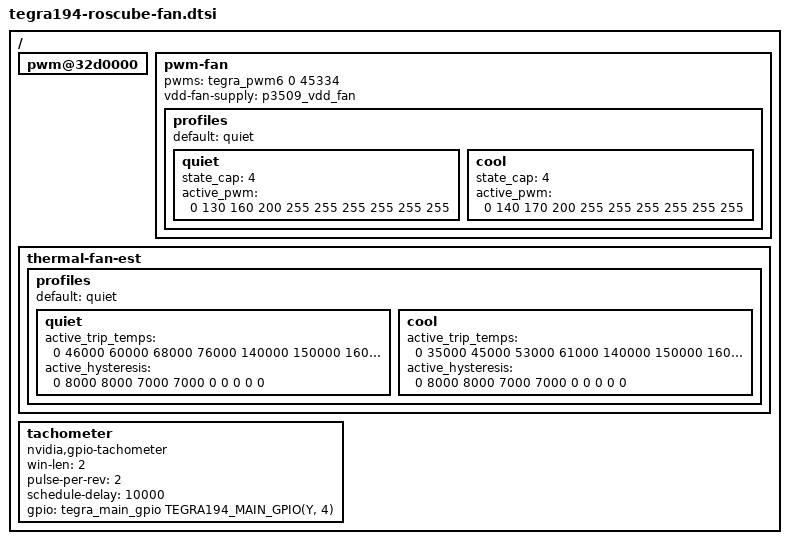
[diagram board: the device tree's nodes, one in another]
/*
 * Copyright (c) 2020, ADLINK Technology Inc. Advanced Robotic Platform Group.  All rights reserved.
 *
 * This program is free software; you can redistribute it and/or modify
 * it under the terms of the GNU General Public License as published by
 * the Free Software Foundation; version 2 of the License.
 *
 * This program is distributed in the hope that it will be useful, but WITHOUT
 * ANY WARRANTY; without even the implied warranty of MERCHANTABILITY or
 * FITNESS FOR A PARTICULAR PURPOSE.  See the GNU General Public License for
 * more details.
 */

 / {

	pwm@32d0000 {
		status = "okay";
	};

	pwm-fan {
		pwms = <&tegra_pwm6 0 45334>;
		vdd-fan-supply = <&p3509_vdd_fan>;
		profiles {
			default = "quiet";
			quiet {
				state_cap = <4>;
				active_pwm = <0 130 160 200 255 255 255 255 255 255>;
			};
			cool {
				state_cap = <4>;
				active_pwm = <0 140 170 200 255 255 255 255 255 255>;
			};
		};
	};
	
	thermal-fan-est {
		profiles {
			default = "quiet";
			quiet {
				active_trip_temps = <0 46000 60000 68000 76000
						140000 150000 160000 170000 180000>;
				active_hysteresis = <0 8000 8000 7000 7000
						0 0 0 0 0>;
			};
			cool {
				active_trip_temps = <0 35000 45000 53000 61000
						140000 150000 160000 170000 180000>;
				active_hysteresis = <0 8000 8000 7000 7000
						0 0 0 0 0>;
			};
		};
	};

    tachometer {
        compatible = "nvidia,gpio-tachometer";
        win-len = <2>;
        pulse-per-rev = <2>;
        schedule-delay = <10000>;
        gpio = <&tegra_main_gpio TEGRA194_MAIN_GPIO(Y, 4) 0>;
        status = "okay";
    };
 };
